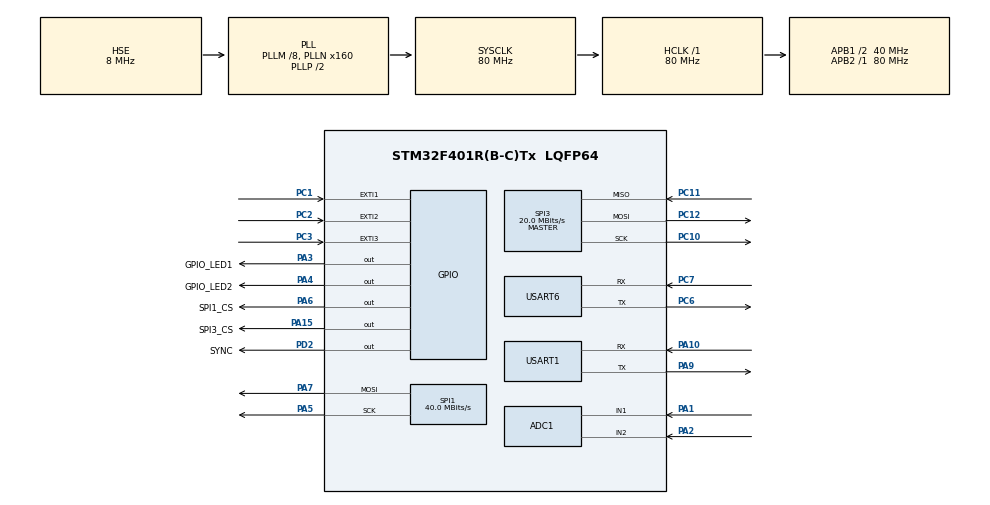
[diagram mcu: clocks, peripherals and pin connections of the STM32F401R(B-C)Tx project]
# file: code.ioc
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Mcu.Family=STM32F4
RCC.CortexFreq_Value=80000000
SPI3.Direction=SPI_DIRECTION_2LINES
SPI3.VirtualType=VM_MASTER
SPI1.VirtualType=VM_MASTER
SH.ADCx_IN2.0=ADC1_IN2,IN2
PC10.Signal=SPI3_SCK
PC12.Signal=SPI3_MOSI
PA6.GPIO_Label=SPI1_CS
RCC.SYSCLKSource=RCC_SYSCLKSOURCE_PLLCLK
ProjectManager.StackSize=0x400
PA15.GPIO_Label=SPI3_CS
PH0\ -\ OSC_IN.Signal=RCC_OSC_IN
SPI1.Direction=SPI_DIRECTION_2LINES
RCC.HCLKFreq_Value=80000000
RCC.APB2TimFreq_Value=80000000
PC7.Signal=USART6_RX
SPI1.CalculateBaudRate=40.0 MBits/s
PC3.Signal=GPXTI3
RCC.AHBFreq_Value=80000000
ADC1.Channel-0\#ChannelRegularConversion=ADC_CHANNEL_1
RCC.HSE_VALUE=8000000
PC14-OSC32_IN.Mode=LSE-External-Oscillator
PA14.Mode=Serial_Wire
ADC1.SamplingTime-0\#ChannelRegularConversion=ADC_SAMPLETIME_3CYCLES
Mcu.Package=LQFP64
PA6.Signal=GPIO_Output
SPI3.Mode=SPI_MODE_MASTER
USART6.VirtualMode=VM_ASYNC
RCC.EnbaleCSS=true
PA10.Signal=USART1_RX
PA15.Signal=GPIO_Output
PC11.Mode=Full_Duplex_Master
SH.ADCx_IN1.0=ADC1_IN1,IN1
RCC.APB1TimFreq_Value=80000000
SPI1.BaudRatePrescaler=SPI_BAUDRATEPRESCALER_2
PA4.GPIO_Label=GPIO_LED2
PA3.Signal=GPIO_Output
PA5.Mode=TX_Only_Simplex_Unidirect_Master
RCC.PLLSourceVirtual=RCC_PLLSOURCE_HSE
PC15-OSC32_OUT.Mode=LSE-External-Oscillator
ADC1.Rank-0\#ChannelRegularConversion=1
PA7.Mode=TX_Only_Simplex_Unidirect_Master
PA10.Mode=Asynchronous
PC11.Signal=SPI3_MISO
PH1\ -\ OSC_OUT.Mode=HSE-External-Oscillator
PC2.Signal=GPXTI2
PC6.Signal=USART6_TX
PC10.Mode=Full_Duplex_Master
RCC.APB1CLKDivider=RCC_HCLK_DIV2
PC14-OSC32_IN.Signal=RCC_OSC32_IN
PA0-WKUP.Signal=SYS_WKUP
PA0-WKUP.Mode=SYS_WakeUp0
PA13.Signal=SYS_JTMS-SWDIO
PA9.Mode=Asynchronous
PH0\ -\ OSC_IN.Mode=HSE-External-Oscillator
ProjectManager.TargetToolchain=Makefile
PC6.Mode=Asynchronous
PA9.Signal=USART1_TX
PC15-OSC32_OUT.Signal=RCC_OSC32_OUT
PA1.Signal=ADCx_IN1
PA5.Signal=SPI1_SCK
PC12.Mode=Full_Duplex_Master
PH1\ -\ OSC_OUT.Signal=RCC_OSC_OUT
board=custom
RCC.VCOOutputFreq_Value=160000000
RCC.APB2Freq_Value=80000000
SPI3.CalculateBaudRate=20.0 MBits/s
SPI1.Mode=SPI_MODE_MASTER
SPI3.BaudRatePrescaler=SPI_BAUDRATEPRESCALER_2
PA13.Mode=Serial_Wire
Mcu.Name=STM32F401R(B-C)Tx
PA2.Signal=ADCx_IN2
RCC.48MHZClocksFreq_Value=40000000
PA4.Signal=GPIO_Output
RCC.SYSCLKFreq_VALUE=80000000
ADC1.master=1
USART1.VirtualMode=VM_ASYNC
PA14.Signal=SYS_JTCK-SWCLK
ProjectManager.HeapSize=0x200
RCC.HSI_VALUE=16000000
NVIC.PriorityGroup=NVIC_PRIORITYGROUP_4
ADC1.NbrOfConversionFlag=1
RCC.PLLM=8
RCC.PLLN=160
PC7.Mode=Asynchronous
PD2.Signal=GPIO_Output
RCC.APB1Freq_Value=40000000
PC1.Signal=GPXTI1
PD2.GPIO_Label=SYNC
PA3.GPIO_Label=GPIO_LED1
PA7.Signal=SPI1_MOSI

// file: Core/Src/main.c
/* USER CODE BEGIN Header */
/**
  ******************************************************************************
  * @file           : main.c
  * @brief          : Main program body
  ******************************************************************************
  * @attention
  *
  * <h2><center>&copy; Copyright (c) 2021 STMicroelectronics.
  * All rights reserved.</center></h2>
  *
  * This software component is licensed by ST under BSD 3-Clause license,
  * the "License"; You may not use this file except in compliance with the
  * License. You may obtain a copy of the License at:
  *                        opensource.org/licenses/BSD-3-Clause
  *
  ******************************************************************************
  */
/* USER CODE END Header */
#include "adc.h"
#include "spi.h"
#include "usart.h"
#include "gpio.h"

/* USER CODE BEGIN Includes */
#include "stdint.h"
/* USER CODE END Includes */

void SystemClock_Config(void);

int main(void)
{

  /* MCU Configuration--------------------------------------------------------*/

  /* Reset of all peripherals, Initializes the Flash interface and the Systick. */
  HAL_Init();

  /* Configure the system clock */
  SystemClock_Config();

  /* Initialize all configured peripherals */
  MX_GPIO_Init();
  MX_ADC1_Init();
  MX_SPI1_Init();
  MX_SPI3_Init();
  MX_USART1_UART_Init();
  MX_USART6_UART_Init();

  /* Infinite loop */
  /* USER CODE BEGIN WHILE */
  while (1)
  {
      HAL_GPIO_WritePin(GPIOA, GPIO_PIN_0, GPIO_PIN_SET);
      HAL_Delay(500);
    /* USER CODE END WHILE */

  }
}

void SystemClock_Config(void)
{
  RCC_OscInitTypeDef RCC_OscInitStruct = {0};
  RCC_ClkInitTypeDef RCC_ClkInitStruct = {0};

  /** Configure the main internal regulator output voltage
  */
  __HAL_RCC_PWR_CLK_ENABLE();
  __HAL_PWR_VOLTAGESCALING_CONFIG(PWR_REGULATOR_VOLTAGE_SCALE2);
  /** Initializes the RCC Oscillators according to the specified parameters
  * in the RCC_OscInitTypeDef structure.
  */
  RCC_OscInitStruct.OscillatorType = RCC_OSCILLATORTYPE_HSE;
  RCC_OscInitStruct.HSEState = RCC_HSE_ON;
  RCC_OscInitStruct.PLL.PLLState = RCC_PLL_ON;
  RCC_OscInitStruct.PLL.PLLSource = RCC_PLLSOURCE_HSE;
  RCC_OscInitStruct.PLL.PLLM = 8;
  RCC_OscInitStruct.PLL.PLLN = 160;
  RCC_OscInitStruct.PLL.PLLP = RCC_PLLP_DIV2;
  RCC_OscInitStruct.PLL.PLLQ = 4;
  if (HAL_RCC_OscConfig(&RCC_OscInitStruct) != HAL_OK)
  {
    Error_Handler();
  }
  /** Initializes the CPU, AHB and APB buses clocks
  */
  RCC_ClkInitStruct.ClockType = RCC_CLOCKTYPE_HCLK|RCC_CLOCKTYPE_SYSCLK
                              |RCC_CLOCKTYPE_PCLK1|RCC_CLOCKTYPE_PCLK2;
  RCC_ClkInitStruct.SYSCLKSource = RCC_SYSCLKSOURCE_PLLCLK;
  RCC_ClkInitStruct.AHBCLKDivider = RCC_SYSCLK_DIV1;
  RCC_ClkInitStruct.APB1CLKDivider = RCC_HCLK_DIV2;
  RCC_ClkInitStruct.APB2CLKDivider = RCC_HCLK_DIV1;

  if (HAL_RCC_ClockConfig(&RCC_ClkInitStruct, FLASH_LATENCY_2) != HAL_OK)
  {
    Error_Handler();
  }
  /** Enables the Clock Security System
  */
  HAL_RCC_EnableCSS();
}

void Error_Handler(void)
{
  __disable_irq();
  while (1)
  {
  }
}

/************************ (C) COPYRIGHT STMicroelectronics *****END OF FILE****/
